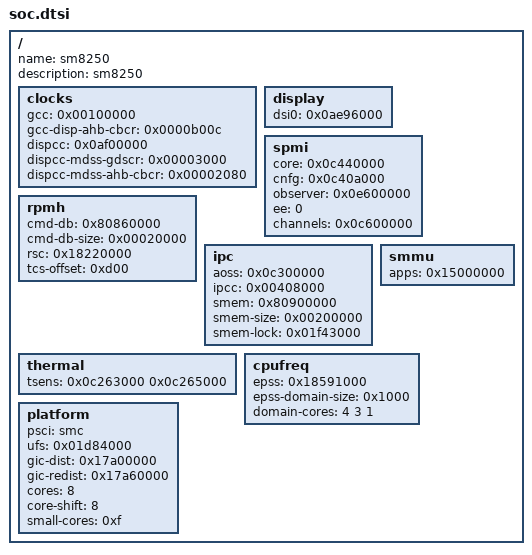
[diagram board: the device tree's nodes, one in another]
/dts-v1/;

// sm8250. Started by tools/boards.py new from pipa-merged.dts.
// What every board with this SoC shares: where its blocks are (Documentation/porting.md).
/ {
	name = "sm8250";
	description = "sm8250";

	// The clocks the display block's registers need before they can be read: for a "dcs" backlight and
	// the feature "display-scan". The addresses are in the tree; the offsets are not -- they are in Linux's
	// clock drivers for the SoC (gcc-CODENAME.c, dispcc-CODENAME.c).
	clocks {
		gcc = <0x00100000>;             // clock-controller@100000 (qcom,CODENAME-gcc); the only key of this section
		                                // that the part drivers need
		gcc-disp-ahb-cbcr = <0x0000b00c>; // GCC_DISP_AHB_CLK: on SM8250 not a modelled branch but one of the
		                                // always-on CBCRs (Linux drivers/clk/qcom/gcc-sm8250.c, gcc_sm8250_critical_cbcrs)
		dispcc = <0x0af00000>;          // clock-controller@af00000 (qcom,CODENAME-dispcc)
		dispcc-mdss-gdscr = <0x00003000>; // mdss_gdsc.gdscr (Linux drivers/clk/qcom/dispcc-sm8250.c)
		dispcc-mdss-ahb-cbcr = <0x00002080>; // disp_cc_mdss_ahb_clk.halt_reg (same file)
	};

	display {
		dsi0 = <0x0ae96000>;            // the first DSI controller (cell-index 0), reg "dsi_ctrl"
	};

	// The PMIC arbiter (qcom,spmi-pmic-arb), by its reg-names: for the features "buttons-pmic",
	// "torch-pm8350c" and "camera-sm7325".
	spmi {
		core = <0x0c440000>;            // "core"
		cnfg = <0x0c40a000>;            // "cnfg"
		observer = <0x0e600000>;        // "obsrvr": reads
		ee = <0>;                       // qcom,ee; optional, 0 if left out
		channels = <0x0c600000>;        // "chnls": writes; optional, needed only by the drivers that write to a PMIC
	};

	// RPMh: for the features "ddr-rpmh", "adsp" and "gpu-a660", and for the part drivers that ask it for a
	// supply (the touch controllers', the speaker amplifier's, the cameras', Wi-Fi's).
	rpmh {
		cmd-db = <0x80860000>;          // the reserved-memory node with compatible "qcom,cmd-db": its address
		cmd-db-size = <0x00020000>;     // ... and size
		rsc = <0x18220000>;             // the qcom,rpmh-rsc with qcom,drv-id = <2> (apps_rsc): its reg "drv-2"
		tcs-offset = <0xd00>;           // qcom,tcs-offset of that node
	};

	// The way to the SoC's other processors, for the features "adsp" and "wifi-wcn6750".
	ipc {
		aoss = <0x0c300000>;            // the always-on processor's mailbox: qcom,qmp-mbox (Linux: qcom,aoss-qmp), its reg
		ipcc = <0x00408000>;            // qcom,ipcc, its reg: what the processors ring each other through
		smem = <0x80900000>;            // the memory they share: the memory-region of the qcom,smem node
		smem-size = <0x00200000>;       // ... and its size
		smem-lock = <0x01f43000>;       // the lock on it: hwlocks = <&tcsr_mutex N> of the qcom,smem node, which is
		                                // N x 0x1000 into the qcom,tcsr-mutex block (0x1f40000 + 3 x 0x1000)
	};

	// The SMMU between the SoC's devices and memory, for the part drivers that give a device its addresses
	// (the speakers' audio path, the cameras, Wi-Fi). The GPU's own is in adreno { }.
	smmu {
		apps = <0x15000000>;            // apps_smmu (the vendor's apps-smmu@15000000; Linux's iommu@15000000)
	};

	// Temperature, for a board's thermal { }.
	thermal {
		tsens = <0x0c263000 0x0c265000>; // the TSENS controllers (at most eight), reg "tsens_tm_physical"
	};

	// The cores' frequency hardware, for the feature "cpufreq-epss" and a board's thermal { }: EPSS on the SM8350,
	// SM7325, SC7280 and every chip after them, the OSM's firmware before it (SDM845, SM8150, SM8250, SC7180,
	// SM6350, SM7225). The node is qcom,cpufreq-epss or qcom,cpufreq-hw (the vendor's qcom,cpufreq-hw-epss or
	// qcom,cpufreq-hw); tools/boards.py new --dts reads it, the layout with it.
	// Linux mainline describes this block as "qcom,sm8250-cpufreq-epss" (arch/arm64/boot/dts/qcom/sm8250.dtsi), which
	// is what was read here; HakiOS's Documentation/chipsets.md lists the SM8250 with the OSM's layout. Which one the
	// hardware answers to is to be seen on the tablet with the driver's look-only level before cpufreq-epss is listed.
	cpufreq {
		epss = <0x18591000>;            // the first of its "freq-domainN" regs
		epss-domain-size = <0x1000>;    // their size (at least 0x324 for EPSS, 0x924 for the OSM), and the distance
		                                // from one to the next unless domains says otherwise
		domain-cores = <4 3 1>;         // how many cores each group has, in the cores' order (the cpu@ nodes'
		                                // qcom,freq-domain); one to four groups, together platform { } cores
	};

	// What the loader (arch/arm64/boot/) tells the kernel of the machine, for boards with a loader { } section.
	platform {
		// io-base = <0x00400000>;      // TO FILL IN for loader { }: one window over the SoC's peripherals, never 0
		// io-size = <0x3fc00000>;      // (these two are what the Snapdragon 7-series ports use)
		psci = "smc";                   // the psci node's method: "smc" or "hvc"
		ufs = <0x01d84000>;             // optional: the UFS host controller (the ufshc node's reg "ufs_mem"), for the
		                                // loader's and the kernel's own requests to the storage (ufs_native=)
		gic-dist = <0x17a00000>;        // the arm,gic-v3 node's reg: its first entry
		gic-redist = <0x17a60000>;      // ... its second
		cores = <8>;                    // the cpu@ nodes
		core-shift = <8>;               // where the core's number is in its reg: 8 for 0x000, 0x100 ..., 0 for 0, 1 ...
		small-cores = <0xf>;            // optional: a bit for each core of the lowest capacity-dmips-mhz
	};
};
